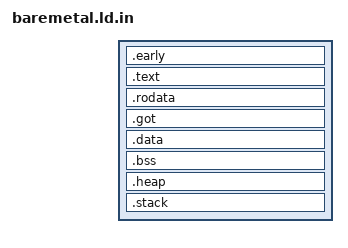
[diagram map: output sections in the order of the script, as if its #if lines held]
/*
 * Copyright (C) 2013 Jeff Kent <jeff@jkent.net>
 *
 * This program is free software; you can redistribute it and/or modify
 * it under the terms of the GNU General Public License version 2 as
 * published by the Free Software Foundation.
 *
 * This program is distributed in the hope that it will be useful,
 * but WITHOUT ANY WARRANTY; without even the implied warranty of
 * MERCHANTABILITY or FITNESS FOR A PARTICULAR PURPOSE.  See the
 * GNU General Public License for more details.
 *
 * You should have received a copy of the GNU General Public License
 * along with this program; if not, write to the Free Software
 * Foundation, Inc., 59 Temple Place, Suite 330, Boston, MA  02111-1307  USA
 */

#include "config.h"

OUTPUT_FORMAT("elf32-littlearm", "elf32-littlearm", "elf32-littlearm")
OUTPUT_ARCH(arm)
ENTRY(_entry)

SECTIONS
{
  . = CONFIG_BAREMETAL_ENTRY_ADDRESS;
  __early_start__ = .;
  .early : {
#if defined(BUILD)
    BUILD/baremetal/entry.o(.text .stub .text.*)
    BUILD/baremetal/early.o(.text .stub .text.*)
    BUILD/baremetal/entry.o(.rodata .rodata.*)
    BUILD/baremetal/early.o(.rodata .rodata.*)
#else
    baremetal/entry.o(.text .stub .text.*)
    baremetal/early.o(.text .stub .text.*)
    baremetal/entry.o(.rodata .rodata.*)
    baremetal/early.o(.rodata .rodata.*)
#endif
  }
#if defined(CONFIG_BAREMETAL_BOOT_SOURCE_UART)
  . = ALIGN(0x4000);
#elif defined(CONFIG_BAREMETAL_BOOT_SOURCE_NAND)
  . = ALIGN(CONFIG_BAREMETAL_NAND_PAGESIZE);
#else
  . = ALIGN(0x8);
#endif
  __early_end__ = .;

#if defined(CONFIG_BAREMETAL_LOAD_ADDRESS)
  . = CONFIG_BAREMETAL_LOAD_ADDRESS;
#endif
  __image_start__ = .;
  .text : AT(__early_end__) {
#if defined(BUILD)
    BUILD/baremetal/startup.o(.text)
#else
    baremetal/startup.o(.text)
#endif
    *(.text.startup .text.startup.*)
    *(.text .stub .text.*)
    *(.glue_7t) *(.glue_7) *(.vfp11_veneer) *(.v4_bx)
  }
  .rodata : {
    *(.rodata .rodata.*)
  }
  .got : {
    *(.got.plt) *(.igot.plt) *(.got) *(.igot)
  }
  .data : {
    *(.data .data.*)
  }
#if defined(CONFIG_BAREMETAL_BOOT_SOURCE_UART)
  . = ALIGN(0x4000);
#elif defined(CONFIG_BAREMETAL_BOOT_SOURCE_NAND)
  . = ALIGN(CONFIG_BAREMETAL_NAND_PAGESIZE);
#else
  . = ALIGN(0x8);
#endif
  __image_end__ = .;

  .bss : {
    __bss_start__ = .;
    *(.bss .bss.*)
    *(COMMON)
#if defined(CONFIG_BAREMETAL_ENABLE_DCACHE)
    main_tlb = ALIGN(0x4000);
    . = main_tlb + 0x4000;
#endif
    . = ALIGN(0x4);
    __bss_end__ = .;
  }

#if defined(CONFIG_BAREMETAL_CLIB_NEWLIB)
  .heap : {
    __heap_start__ = .;
    . += CONFIG_BAREMETAL_HEAP_SIZE;
    . = ALIGN(0x4);
    __heap_end__ = .;
  }
#endif

  .stack : {
    __stack_end__ = .;
    . += CONFIG_BAREMETAL_STACK_SIZE;
    . = ALIGN(0x4);
    __stack_top__ = .;
  }
}

